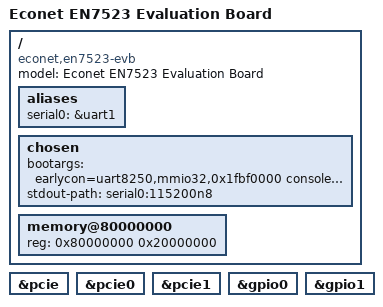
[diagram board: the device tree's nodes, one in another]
// SPDX-License-Identifier: GPL-2.0
/dts-v1/;
#include "en7523.dtsi"

/ {
	model = "Econet EN7523 Evaluation Board";
	compatible = "econet,en7523-evb", "econet,en7523";

	aliases {
		serial0 = &uart1;
	};

	chosen {
		bootargs = "earlycon=uart8250,mmio32,0x1fbf0000 console=ttyS0,115200";
		stdout-path = "serial0:115200n8";
	};

	memory@80000000 {
		device_type = "memory";
		reg = <0x80000000 0x20000000>;
	};
};

&pcie {
	status = "okay";
};

&pcie0 {
	status = "okay";
};

&pcie1 {
	status = "okay";
};

&gpio0 {
	status = "okay";
};

&gpio1 {
	status = "okay";
};
